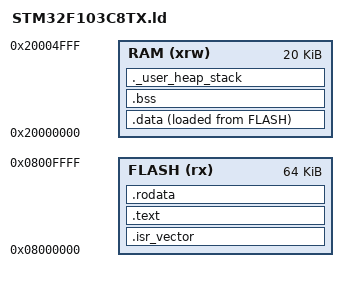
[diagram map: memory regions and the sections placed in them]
/* Entry Point */
ENTRY(Reset_Handler)

/* Memories definition */
MEMORY
{
  RAM    (xrw)    : ORIGIN = 0x20000000,   LENGTH = 20K
  FLASH    (rx)    : ORIGIN = 0x8000000,   LENGTH = 64K
}

/* Highest address of the user mode stack */
_estack = ORIGIN(RAM) + LENGTH(RAM); /* end of "RAM" Ram type memory */

_Min_Heap_Size = 0x200; /* required amount of heap */
_Min_Stack_Size = 0x400; /* required amount of stack */

/* Sections */
SECTIONS{
    /* The startup code into "FLASH" Rom type memory */
  .isr_vector :
  {
    . = ALIGN(4);
    KEEP(*(.isr_vector)) /* Startup code */
    . = ALIGN(4);
  } >FLASH

  /* The program code and other data into "FLASH" Rom type memory */
  .text :{*(.text*)} >FLASH

  /* Constant data into "FLASH" Rom type memory */
  .rodata : { *(.rodata*) } >FLASH

  /* Used by the startup to initialize data */
  _sidata = LOADADDR(.data);

  /* Initialized data sections into "RAM" Ram type memory */
  .data :
  {
    . = ALIGN(4);
    _sdata = .;        /* create a global symbol at data start */
    *(.data*)          /* .data* sections */
    . = ALIGN(4);
    _edata = .;        /* define a global symbol at data end */

  } >RAM AT> FLASH

  /* Uninitialized data section into "RAM" Ram type memory */
  
  .bss : {
    . = ALIGN(4);
    _sbss = .;                                   /* .bss section start */
    *(.bss SORT(.bss.*) COMMON)
    . = ALIGN(4);
    _ebss = .;                                   /* .bss section end */
  } >RAM

  /* User_heap_stack section, used to check that there is enough "RAM" Ram  type memory left */
  ._user_heap_stack :
  {
    . = ALIGN(8);
    PROVIDE ( end = . );
    PROVIDE ( _end = . );
    . = . + _Min_Heap_Size;
    . = . + _Min_Stack_Size;
    . = ALIGN(8);
  } >RAM

  _end = .;  
}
